AUTOSAR XML (schema 4-3-0)
package /MICROSAR/Det_swc/Interfaces
  client server interface DETServiceLegacy: is-service=true, service-kind=DEVELOPMENT-ERROR-TRACER
    operation ReportError: possible-error=DETServiceLegacy/E_OK
      arg InstanceId: type=uint8, direction=IN
      arg ApiId: type=uint8, direction=IN
      arg ErrorId: type=uint8, direction=IN
    error E_OK: error-code=0
  client server interface DETService: is-service=true, service-kind=DEVELOPMENT-ERROR-TRACER
    operation ReportError: possible-error=DETService/E_OK
      arg ApiId: type=uint8, direction=IN
      arg ErrorId: type=uint8, direction=IN
    operation ReportRuntimeError: possible-error=DETService/E_OK
      arg ApiId: type=uint8, direction=IN
      arg ErrorId: type=uint8, direction=IN
    error E_OK: error-code=0
package /MICROSAR/Det_swc/ComponentTypes
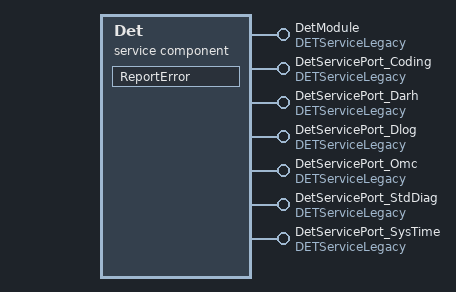
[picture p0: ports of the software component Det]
  service sw component type Det: category=SERVICE_COMPONENT
    7 x provide port, all with provided-interface=DETServiceLegacy:
      DetModule
      DetServicePort_Coding
      DetServicePort_Darh
      DetServicePort_Dlog
      DetServicePort_Omc
      DetServicePort_StdDiag
      DetServicePort_SysTime
    behavior DetInternalBehavior: handle-termination-and-restart=NO-SUPPORT
      7 x operation invoked event, all with start-on-event=ReportError:
        OpEventReportError_ReportError_DetModule: operation=DetModule.ReportError
        OpEventReportError_ReportError_DetServicePort_Coding: operation=DetServicePort_Coding.ReportError
        OpEventReportError_ReportError_DetServicePort_Darh: operation=DetServicePort_Darh.ReportError
        OpEventReportError_ReportError_DetServicePort_Dlog: operation=DetServicePort_Dlog.ReportError
        OpEventReportError_ReportError_DetServicePort_Omc: operation=DetServicePort_Omc.ReportError
        OpEventReportError_ReportError_DetServicePort_StdDiag: operation=DetServicePort_StdDiag.ReportError
        OpEventReportError_ReportError_DetServicePort_SysTime: operation=DetServicePort_SysTime.ReportError
      port-api-options:
        {enable-take-address=true, indirect-api=false, port-defined-argument-value{value=4101, value-type=uint16}, port=DetServicePort_StdDiag}
        {enable-take-address=true, indirect-api=false, port-defined-argument-value{value=4096, value-type=uint16}, port=DetModule}
        {enable-take-address=true, indirect-api=false, port-defined-argument-value{value=4097, value-type=uint16}, port=DetServicePort_Coding}
        {enable-take-address=true, indirect-api=false, port-defined-argument-value{value=4098, value-type=uint16}, port=DetServicePort_Darh}
        {enable-take-address=true, indirect-api=false, port-defined-argument-value{value=4099, value-type=uint16}, port=DetServicePort_Dlog}
        {enable-take-address=true, indirect-api=false, port-defined-argument-value{value=4100, value-type=uint16}, port=DetServicePort_Omc}
        {enable-take-address=true, indirect-api=false, port-defined-argument-value{value=4102, value-type=uint16}, port=DetServicePort_SysTime}
      runnable ReportError: can-be-invoked-concurrently=true, symbol=Det_ReportError
  swc implementation DetImplementation: programming-language=C, behavior=DetInternalBehavior
